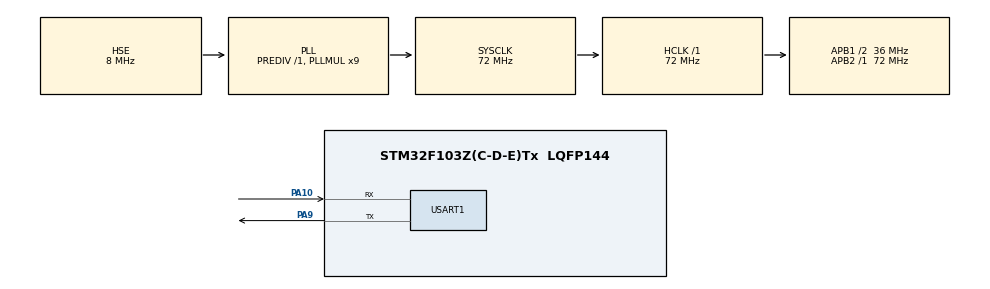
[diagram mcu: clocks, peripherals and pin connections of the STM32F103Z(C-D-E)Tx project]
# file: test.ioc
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Mcu.Family=STM32F1
Mcu.Name=STM32F103Z(C-D-E)Tx
Mcu.Package=LQFP144
NVIC.PriorityGroup=NVIC_PRIORITYGROUP_4
OSC_IN.Mode=HSE-External-Oscillator
OSC_IN.Signal=RCC_OSC_IN
OSC_OUT.Mode=HSE-External-Oscillator
OSC_OUT.Signal=RCC_OSC_OUT
PA10.Mode=Asynchronous
PA10.Signal=USART1_RX
PA13.Mode=JTAG_4_pins
PA13.Signal=SYS_JTMS-SWDIO
PA14.Mode=JTAG_4_pins
PA14.Signal=SYS_JTCK-SWCLK
PA15.Mode=JTAG_4_pins
PA15.Signal=SYS_JTDI
PA9.Mode=Asynchronous
PA9.Signal=USART1_TX
PB3.Mode=JTAG_4_pins
PB3.Signal=SYS_JTDO-TRACESWO
ProjectManager.HeapSize=0x200
ProjectManager.StackSize=0x400
ProjectManager.TargetToolchain=MDK-ARM V5
RCC.AHBFreq_Value=72000000
RCC.APB1CLKDivider=RCC_HCLK_DIV2
RCC.APB1Freq_Value=36000000
RCC.APB1TimFreq_Value=72000000
RCC.APB2Freq_Value=72000000
RCC.APB2TimFreq_Value=72000000
RCC.HCLKFreq_Value=72000000
RCC.PLLMUL=RCC_PLL_MUL9
RCC.PLLSourceVirtual=RCC_PLLSOURCE_HSE
RCC.SYSCLKFreq_VALUE=72000000
RCC.SYSCLKSource=RCC_SYSCLKSOURCE_PLLCLK
RCC.USBFreq_Value=72000000
USART1.VirtualMode=VM_ASYNC
board=custom

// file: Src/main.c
/* USER CODE BEGIN Header */
/**
  ******************************************************************************
  * @file           : main.c
  * @brief          : Main program body
  ******************************************************************************
  * @attention
  *
  * <h2><center>&copy; Copyright (c) 2022 STMicroelectronics.
  * All rights reserved.</center></h2>
  *
  * This software component is licensed by ST under BSD 3-Clause license,
  * the "License"; You may not use this file except in compliance with the
  * License. You may obtain a copy of the License at:
  *                        opensource.org/licenses/BSD-3-Clause
  *
  ******************************************************************************
  */
/* USER CODE END Header */

#include "main.h"
#include "usart.h"
#include "gpio.h"

/* USER CODE BEGIN Includes */
#include <stdio.h>
#include <string.h>
#include <stdlib.h>

/* USER CODE END Includes */

void SystemClock_Config(void);

/* USER CODE BEGIN 0 */
#define container_of(ptr, type, member) \
	(type *)((char *)ptr - (unsigned int)&((type *)0)->member)

struct node_t {
	struct node_t *pre;
	struct node_t *next;
};

struct person {
	char *name;
	int age;
	struct node_t node;
};

struct list {
	char *name; /* A班 */
	struct node_t head;
};

void InitList(struct list *pList, char *name)
{
	pList->name = name;
	pList->head.next = &pList->head;
	pList->head.pre  = &pList->head;
}

void AddItemToList(struct list *pList, struct node_t *new_node)
{
	struct node_t *last = pList->head.pre;

	new_node->next  = &pList->head;
	last->next      = new_node;
	new_node->pre   = last;
	pList->head.pre = new_node;
}

void AddItemAfter(struct node_t *pre, struct node_t *new_node)
{
	struct node_t *right = pre->next;

	pre->next = new_node;
	new_node->next = right;

	right->pre = new_node;
	new_node->pre = pre;
}

void DelItemFromList(struct list *pList, struct node_t *node)
{
	struct node_t *left  = node->pre;
	struct node_t *right = node->next;

	left->next = right;
	right->pre = left;
}

int CmpPersonAge(struct node_t *pre, struct node_t *next)
{
	struct person *p;
	struct person *n;

	p = container_of(pre, struct person, node);
	n = container_of(next, struct person, node);

	if (p->age < n->age)
		return -1;
	else
		return 0;
}

void SortList(struct list *pList)
{
	struct node_t *pre1 = &pList->head;
	struct node_t *pre2;
	struct node_t *cur = pre1->next;
	struct node_t *next;
	struct node_t *tmp;

	while (cur != &pList->head)
	{
		pre2 = cur;
		next = cur->next;
		while (next != &pList->head)
		{
			if (CmpPersonAge(cur, next) == 0)
			{
				/* 交换节点 */
				/* 1. del cur */
				DelItemFromList(pList, cur);

				/* 2. del next */
				DelItemFromList(pList, next);

				/* 3. 在pre1之后插入next */
				AddItemAfter(pre1, next);

				/* 4. 在pre2之后插入cur */
				if (pre2 == cur)
					AddItemAfter(next, cur);
				else
					AddItemAfter(pre2, cur);

				/* 5. cur/next指针互换 */
				tmp = cur;
				cur = next;
				next = tmp;
			}

			pre2 = next;
			next = next->next;
		}

		pre1 = cur;
		cur = cur->next;
	}

}

void PrintList(struct list *pList)
{
	int i = 0;

	struct node_t *node = pList->head.next;
	struct person *p;

	while (node != &pList->head)
	{
		p = container_of(node, struct person, node);
		printf("person %d: %s is %d\r\n", i++, p->name, p->age);

		/* 后面还有人, 移动到下一个 */
		node = node->next;
	}
}
/* USER CODE END 0 */

int main(void)
{
  /* USER CODE BEGIN 1 */
	struct list a_list;
	int i;

	struct person p[] = {
		{"p1", 10, {NULL}},
		{"p2", 20, {NULL}},
		{"p3", 13, {NULL}},
		{"p4", 41, {NULL}},
		{"p5", 56, {NULL}},
		{"p6", 12, {NULL}},
		{"p7", 9, {NULL}},
		{"p8", 21, {NULL}},
		{"p9", 22, {NULL}},
		{"p10", 21, {NULL}},
		{"p11", 20, {NULL}},
		{NULL, 0, {NULL}},
	};
  /* USER CODE END 1 */

  /* MCU Configuration--------------------------------------------------------*/

  /* Reset of all peripherals, Initializes the Flash interface and the Systick. */
  HAL_Init();

  /* Configure the system clock */
  SystemClock_Config();

  /* Initialize all configured peripherals */
  MX_GPIO_Init();
  MX_USART1_UART_Init();
  /* USER CODE BEGIN 2 */
	InitList(&a_list, "A_class");

	i = 0;
	while (p[i].name != NULL)
	{
		AddItemToList(&a_list, &p[i].node);
		i++;
	}

	printf("add all person:\r\n");
	PrintList(&a_list);

	DelItemFromList(&a_list, &p[3].node);

	printf("del person %s:\r\n", p[3].name);
	PrintList(&a_list);

	DelItemFromList(&a_list, &p[0].node);

	printf("del person %s:\r\n", p[0].name);
	PrintList(&a_list);

	SortList(&a_list);
	printf("sort list, all person:\r\n");
	PrintList(&a_list);

  /* USER CODE END 2 */

  /* Infinite loop */
  while (1)
  {

  }
}

void SystemClock_Config(void)
{
  RCC_OscInitTypeDef RCC_OscInitStruct = {0};
  RCC_ClkInitTypeDef RCC_ClkInitStruct = {0};

  /** Initializes the CPU, AHB and APB busses clocks
  */
  RCC_OscInitStruct.OscillatorType = RCC_OSCILLATORTYPE_HSE;
  RCC_OscInitStruct.HSEState = RCC_HSE_ON;
  RCC_OscInitStruct.HSEPredivValue = RCC_HSE_PREDIV_DIV1;
  RCC_OscInitStruct.HSIState = RCC_HSI_ON;
  RCC_OscInitStruct.PLL.PLLState = RCC_PLL_ON;
  RCC_OscInitStruct.PLL.PLLSource = RCC_PLLSOURCE_HSE;
  RCC_OscInitStruct.PLL.PLLMUL = RCC_PLL_MUL9;
  if (HAL_RCC_OscConfig(&RCC_OscInitStruct) != HAL_OK)
  {
    Error_Handler();
  }
  /** Initializes the CPU, AHB and APB busses clocks
  */
  RCC_ClkInitStruct.ClockType = RCC_CLOCKTYPE_HCLK|RCC_CLOCKTYPE_SYSCLK
                              |RCC_CLOCKTYPE_PCLK1|RCC_CLOCKTYPE_PCLK2;
  RCC_ClkInitStruct.SYSCLKSource = RCC_SYSCLKSOURCE_PLLCLK;
  RCC_ClkInitStruct.AHBCLKDivider = RCC_SYSCLK_DIV1;
  RCC_ClkInitStruct.APB1CLKDivider = RCC_HCLK_DIV2;
  RCC_ClkInitStruct.APB2CLKDivider = RCC_HCLK_DIV1;

  if (HAL_RCC_ClockConfig(&RCC_ClkInitStruct, FLASH_LATENCY_2) != HAL_OK)
  {
    Error_Handler();
  }
}

void Error_Handler(void)
{
}

/************************ (C) COPYRIGHT STMicroelectronics *****END OF FILE****/
